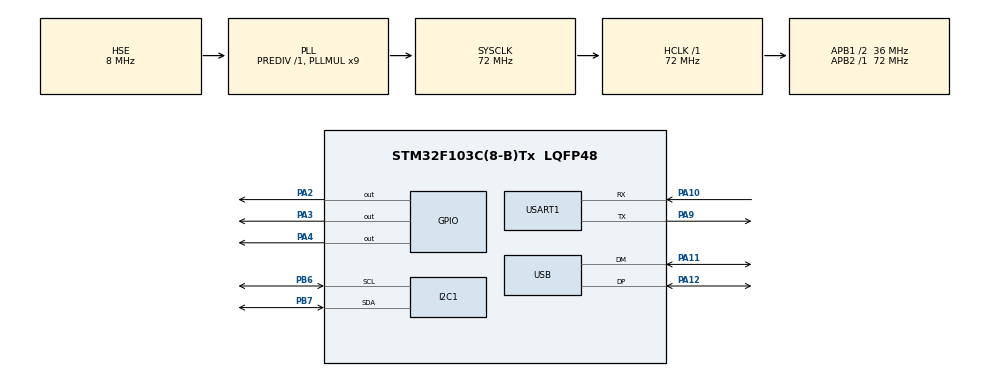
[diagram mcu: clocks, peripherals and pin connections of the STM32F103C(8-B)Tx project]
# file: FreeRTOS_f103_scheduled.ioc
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FREERTOS.Tasks01=ReadMPU6050,1,128,StartReadMPU6050,Default,NULL,Dynamic,NULL,NULL;CalculatePID,0,128,StartCalculatePID,Default,NULL,Dynamic,NULL,NULL;ControllESC,0,128,StartControllESC,Default,NULL,Dynamic,NULL,NULL
FREERTOS.configUSE_NEWLIB_REENTRANT=1
Mcu.Family=STM32F1
Mcu.Name=STM32F103C(8-B)Tx
Mcu.Package=LQFP48
NVIC.PriorityGroup=NVIC_PRIORITYGROUP_4
NVIC.TIM3_IRQn=true\:15\:0\:false\:false\:true\:false\:false\:true\:true
NVIC.TimeBase=TIM3_IRQn
NVIC.TimeBaseIP=TIM3
NVIC.USB_LP_CAN1_RX0_IRQn=true\:5\:0\:false\:false\:true\:true\:false\:true\:true
PA10.Mode=Asynchronous
PA10.Signal=USART1_RX
PA11.Mode=Device
PA11.Signal=USB_DM
PA12.Mode=Device
PA12.Signal=USB_DP
PA13.Mode=Serial_Wire
PA13.Signal=SYS_JTMS-SWDIO
PA14.Mode=Serial_Wire
PA14.Signal=SYS_JTCK-SWCLK
PA2.Signal=GPIO_Output
PA3.Signal=GPIO_Output
PA4.Signal=GPIO_Output
PA9.Mode=Asynchronous
PA9.Signal=USART1_TX
PB6.Mode=I2C
PB6.Signal=I2C1_SCL
PB7.Mode=I2C
PB7.Signal=I2C1_SDA
PD0-OSC_IN.Mode=HSE-External-Oscillator
PD0-OSC_IN.Signal=RCC_OSC_IN
PD1-OSC_OUT.Mode=HSE-External-Oscillator
PD1-OSC_OUT.Signal=RCC_OSC_OUT
ProjectManager.HeapSize=0x200
ProjectManager.StackSize=0x400
ProjectManager.TargetToolchain=STM32CubeIDE
RCC.AHBFreq_Value=72000000
RCC.APB1CLKDivider=RCC_HCLK_DIV2
RCC.APB1Freq_Value=36000000
RCC.APB1TimFreq_Value=72000000
RCC.APB2Freq_Value=72000000
RCC.APB2TimFreq_Value=72000000
RCC.HCLKFreq_Value=72000000
RCC.PLLMUL=RCC_PLL_MUL9
RCC.PLLSourceVirtual=RCC_PLLSOURCE_HSE
RCC.SYSCLKFreq_VALUE=72000000
RCC.SYSCLKSource=RCC_SYSCLKSOURCE_PLLCLK
RCC.USBFreq_Value=72000000
USART1.VirtualMode=VM_ASYNC
USB_DEVICE.CLASS_NAME_FS=DFU
USB_DEVICE.VirtualMode=Dfu
USB_DEVICE.VirtualModeFS=Dfu_FS
VP_FREERTOS_VS_CMSIS_V1.Mode=CMSIS_V1
VP_SYS_VS_tim3.Mode=TIM3
VP_USB_DEVICE_VS_USB_DEVICE_DFU_FS.Mode=DFU_FS
board=custom

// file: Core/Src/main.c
/* USER CODE BEGIN Header */
/**
  ******************************************************************************
  * @file           : main.c
  * @brief          : Main program body
  ******************************************************************************
  * @attention
  *
  * Copyright (c) 2023 STMicroelectronics.
  * All rights reserved.
  *
  * This software is licensed under terms that can be found in the LICENSE file
  * in the root directory of this software component.
  * If no LICENSE file comes with this software, it is provided AS-IS.
  *
  ******************************************************************************
  */
/* USER CODE END Header */
#include "main.h"
#include "cmsis_os.h"
#include "usb_device.h"

I2C_HandleTypeDef hi2c1;

UART_HandleTypeDef huart1;

osThreadId ReadMPU6050Handle;
osThreadId CalculatePIDHandle;
osThreadId ControllESCHandle;

void SystemClock_Config(void);
static void MX_GPIO_Init(void);
static void MX_I2C1_Init(void);
static void MX_USART1_UART_Init(void);
void StartReadMPU6050(void const * argument);
void StartCalculatePID(void const * argument);
void StartControllESC(void const * argument);

int main(void)
{

  /* MCU Configuration--------------------------------------------------------*/

  /* Reset of all peripherals, Initializes the Flash interface and the Systick. */
  HAL_Init();

  /* Configure the system clock */
  SystemClock_Config();

  /* Initialize all configured peripherals */
  MX_GPIO_Init();
  MX_I2C1_Init();
  MX_USART1_UART_Init();

  /* Create the thread(s) */
  /* definition and creation of ReadMPU6050 */
  osThreadDef(ReadMPU6050, StartReadMPU6050, osPriorityAboveNormal, 0, 128);
  ReadMPU6050Handle = osThreadCreate(osThread(ReadMPU6050), NULL);

  /* definition and creation of CalculatePID */
  osThreadDef(CalculatePID, StartCalculatePID, osPriorityNormal, 0, 128);
  CalculatePIDHandle = osThreadCreate(osThread(CalculatePID), NULL);

  /* definition and creation of ControllESC */
  osThreadDef(ControllESC, StartControllESC, osPriorityNormal, 0, 128);
  ControllESCHandle = osThreadCreate(osThread(ControllESC), NULL);

  /* Start scheduler */
  osKernelStart();

  /* We should never get here as control is now taken by the scheduler */
  /* Infinite loop */
  while (1)
  {

  }
}

void SystemClock_Config(void)
{
  RCC_OscInitTypeDef RCC_OscInitStruct = {0};
  RCC_ClkInitTypeDef RCC_ClkInitStruct = {0};
  RCC_PeriphCLKInitTypeDef PeriphClkInit = {0};

  /** Initializes the RCC Oscillators according to the specified parameters
  * in the RCC_OscInitTypeDef structure.
  */
  RCC_OscInitStruct.OscillatorType = RCC_OSCILLATORTYPE_HSE;
  RCC_OscInitStruct.HSEState = RCC_HSE_ON;
  RCC_OscInitStruct.HSEPredivValue = RCC_HSE_PREDIV_DIV1;
  RCC_OscInitStruct.HSIState = RCC_HSI_ON;
  RCC_OscInitStruct.PLL.PLLState = RCC_PLL_ON;
  RCC_OscInitStruct.PLL.PLLSource = RCC_PLLSOURCE_HSE;
  RCC_OscInitStruct.PLL.PLLMUL = RCC_PLL_MUL9;
  if (HAL_RCC_OscConfig(&RCC_OscInitStruct) != HAL_OK)
  {
    Error_Handler();
  }

  /** Initializes the CPU, AHB and APB buses clocks
  */
  RCC_ClkInitStruct.ClockType = RCC_CLOCKTYPE_HCLK|RCC_CLOCKTYPE_SYSCLK
                              |RCC_CLOCKTYPE_PCLK1|RCC_CLOCKTYPE_PCLK2;
  RCC_ClkInitStruct.SYSCLKSource = RCC_SYSCLKSOURCE_PLLCLK;
  RCC_ClkInitStruct.AHBCLKDivider = RCC_SYSCLK_DIV1;
  RCC_ClkInitStruct.APB1CLKDivider = RCC_HCLK_DIV2;
  RCC_ClkInitStruct.APB2CLKDivider = RCC_HCLK_DIV1;

  if (HAL_RCC_ClockConfig(&RCC_ClkInitStruct, FLASH_LATENCY_2) != HAL_OK)
  {
    Error_Handler();
  }
  PeriphClkInit.PeriphClockSelection = RCC_PERIPHCLK_USB;
  PeriphClkInit.UsbClockSelection = RCC_USBCLKSOURCE_PLL;
  if (HAL_RCCEx_PeriphCLKConfig(&PeriphClkInit) != HAL_OK)
  {
    Error_Handler();
  }
}

static void MX_I2C1_Init(void)
{

  hi2c1.Instance = I2C1;
  hi2c1.Init.ClockSpeed = 100000;
  hi2c1.Init.DutyCycle = I2C_DUTYCYCLE_2;
  hi2c1.Init.OwnAddress1 = 0;
  hi2c1.Init.AddressingMode = I2C_ADDRESSINGMODE_7BIT;
  hi2c1.Init.DualAddressMode = I2C_DUALADDRESS_DISABLE;
  hi2c1.Init.OwnAddress2 = 0;
  hi2c1.Init.GeneralCallMode = I2C_GENERALCALL_DISABLE;
  hi2c1.Init.NoStretchMode = I2C_NOSTRETCH_DISABLE;
  if (HAL_I2C_Init(&hi2c1) != HAL_OK)
  {
    Error_Handler();
  }

}

static void MX_USART1_UART_Init(void)
{

  huart1.Instance = USART1;
  huart1.Init.BaudRate = 115200;
  huart1.Init.WordLength = UART_WORDLENGTH_8B;
  huart1.Init.StopBits = UART_STOPBITS_1;
  huart1.Init.Parity = UART_PARITY_NONE;
  huart1.Init.Mode = UART_MODE_TX_RX;
  huart1.Init.HwFlowCtl = UART_HWCONTROL_NONE;
  huart1.Init.OverSampling = UART_OVERSAMPLING_16;
  if (HAL_UART_Init(&huart1) != HAL_OK)
  {
    Error_Handler();
  }

}

static void MX_GPIO_Init(void)
{
  GPIO_InitTypeDef GPIO_InitStruct = {0};

  /* GPIO Ports Clock Enable */
  __HAL_RCC_GPIOD_CLK_ENABLE();
  __HAL_RCC_GPIOA_CLK_ENABLE();
  __HAL_RCC_GPIOB_CLK_ENABLE();

  /*Configure GPIO pin Output Level */
  HAL_GPIO_WritePin(GPIOA, GPIO_PIN_2|GPIO_PIN_3|GPIO_PIN_4, GPIO_PIN_RESET);

  /*Configure GPIO pins : PA2 PA3 PA4 */
  GPIO_InitStruct.Pin = GPIO_PIN_2|GPIO_PIN_3|GPIO_PIN_4;
  GPIO_InitStruct.Mode = GPIO_MODE_OUTPUT_PP;
  GPIO_InitStruct.Pull = GPIO_NOPULL;
  GPIO_InitStruct.Speed = GPIO_SPEED_FREQ_LOW;
  HAL_GPIO_Init(GPIOA, &GPIO_InitStruct);

}

void StartReadMPU6050(void const * argument)
{
  /* init code for USB_DEVICE */
  MX_USB_DEVICE_Init();
  /* USER CODE BEGIN 5 */
  /* Infinite loop */
  for(;;)
  {
	    HAL_GPIO_TogglePin(GPIOA, GPIO_PIN_2);
    osDelay(100);
  }
  /* USER CODE END 5 */
}

void StartCalculatePID(void const * argument)
{
  /* USER CODE BEGIN StartCalculatePID */
  /* Infinite loop */
  for(;;)
  {
	    HAL_GPIO_TogglePin(GPIOA, GPIO_PIN_3);
    osDelay(150);
  }
  /* USER CODE END StartCalculatePID */
}

void StartControllESC(void const * argument)
{
  /* USER CODE BEGIN StartControllESC */
  /* Infinite loop */
  for(;;)
  {
	    HAL_GPIO_TogglePin(GPIOA, GPIO_PIN_4);
    osDelay(200);
  }
  /* USER CODE END StartControllESC */
}

void HAL_TIM_PeriodElapsedCallback(TIM_HandleTypeDef *htim)
{
  if (htim->Instance == TIM3) {
    HAL_IncTick();
  }
}

void Error_Handler(void)
{
  __disable_irq();
  while (1)
  {
  }
}
